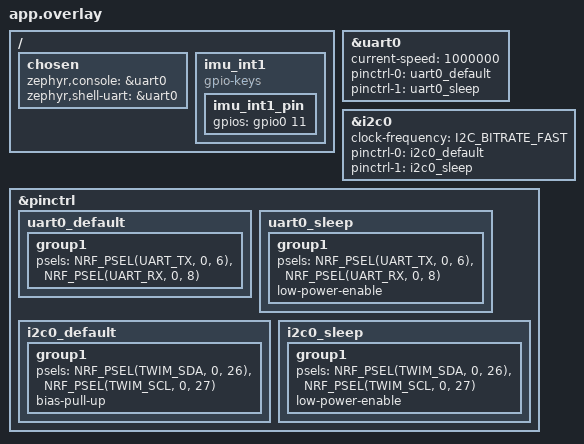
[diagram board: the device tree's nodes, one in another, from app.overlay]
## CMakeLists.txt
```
cmake_minimum_required(VERSION 3.20.0)

find_package(Zephyr REQUIRED HINTS $ENV{ZEPHYR_BASE})

project(imusensor1)

target_sources(app PRIVATE
    src/main.c
    src/imu.c
)

target_include_directories(app PRIVATE
    include
)
```

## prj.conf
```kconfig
CONFIG_MAIN_STACK_SIZE=4096

CONFIG_I2C=y
CONFIG_GPIO=y

CONFIG_LOG=y
CONFIG_LOG_MODE_DEFERRED=y
CONFIG_LOG_DEFAULT_LEVEL=3

CONFIG_CBPRINTF_FP_SUPPORT=y

CONFIG_SERIAL=y
CONFIG_UART_CONSOLE=y
CONFIG_CONSOLE=y
CONFIG_PRINTK=y

CONFIG_LOG_BUFFER_SIZE=32768
CONFIG_LOG_MODE_OVERFLOW=y
CONFIG_LOG_PROCESS_THREAD_STACK_SIZE=4096

CONFIG_NEWLIB_LIBC=y
```

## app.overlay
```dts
/ {
    chosen {
        zephyr,console = &uart0;
        zephyr,shell-uart = &uart0;
    };
};

&uart0 {
    status = "okay";

    current-speed = <1000000>;

    pinctrl-0 = <&uart0_default>;
    pinctrl-1 = <&uart0_sleep>;
    pinctrl-names = "default", "sleep";
};

&i2c0 {
    status = "okay";

    clock-frequency = <I2C_BITRATE_FAST>;

    pinctrl-0 = <&i2c0_default>;
    pinctrl-1 = <&i2c0_sleep>;
    pinctrl-names = "default", "sleep";
};

&pinctrl {

    uart0_default: uart0_default {
        group1 {
            psels = <NRF_PSEL(UART_TX, 0, 6)>,
                    <NRF_PSEL(UART_RX, 0, 8)>;
        };
    };

    uart0_sleep: uart0_sleep {
        group1 {
            psels = <NRF_PSEL(UART_TX, 0, 6)>,
                    <NRF_PSEL(UART_RX, 0, 8)>;
            low-power-enable;
        };
    };

    i2c0_default: i2c0_default {
        group1 {
            psels = <NRF_PSEL(TWIM_SDA, 0, 26)>,
                    <NRF_PSEL(TWIM_SCL, 0, 27)>;
            bias-pull-up;
        };
    };

    i2c0_sleep: i2c0_sleep {
        group1 {
            psels = <NRF_PSEL(TWIM_SDA, 0, 26)>,
                    <NRF_PSEL(TWIM_SCL, 0, 27)>;
            low-power-enable;
        };
    };
};

/* IMU INT1 pin declaration for Zephyr DT.
 * "gpio-keys" is used here only because it is one of the bindings
 * that correctly declares "gpios" as a phandle-array property so
 * GPIO_DT_SPEC_GET()/DT_NODELABEL() resolve correctly. The
 * gpio-keys DRIVER (zephyr,code, key-press semantics, the
 * INPUT subsystem) is NOT used - this pin is read and configured
 * directly via gpio_pin_*() calls in imu.c. */
/ {
    imu_int1 {
        compatible = "gpio-keys";

        imu_int1_pin: imu_int1_pin {
            gpios = <&gpio0 11 GPIO_ACTIVE_HIGH>;
        };
    };
};
```

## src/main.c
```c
#include <zephyr/kernel.h>
#include <zephyr/logging/log.h>
#include <zephyr/sys/printk.h>
#include <zephyr/drivers/gpio.h>  /* Added for onboard LED interaction */

#include "imu.h"

LOG_MODULE_REGISTER(main, LOG_LEVEL_INF);

static uint8_t i2c_error_count = 0U;

/* Devicetree node fetching for the standard onboard nRF LED */
static const struct gpio_dt_spec onboard_led = 
    GPIO_DT_SPEC_GET(DT_ALIAS(led0), gpios);

/* Non-blocking timestamp trackers for the 5-second LED event */
static int64_t blink_end_timestamp = 0;
static int64_t next_toggle_timestamp = 0;
static bool led_is_active = false;

/* Frames to align asynchronous Accel/Gyro FIFO packets */
static struct imu_data current_frame;
static bool has_accel = false;
static bool has_gyro = false;

/*------------------------------------------------------------------
 * Continuous FIFO Flushing
 * Always active. Empties raw hardware frames as they fill up.
 *-----------------------------------------------------------------*/
static void process_fifo_stream(void)
{
    uint16_t words_in_fifo = 0;

    if (imu_get_fifo_sample_count(&words_in_fifo) != 0 || words_in_fifo == 0)
    {
        return;
    }

    struct imu_data packet;
    bool accel_ready;
    bool gyro_ready;

    for (uint16_t i = 0; i < words_in_fifo; i++)
    {
        if (imu_read_fifo_packet(&packet, &accel_ready, &gyro_ready) == 0)
        {
            if (accel_ready)
            {
                current_frame.ax_g = packet.ax_g;
                current_frame.ay_g = packet.ay_g;
                current_frame.az_g = packet.az_g;
                has_accel = true;
            }
            if (gyro_ready)
            {
                current_frame.gx_dps = packet.gx_dps;
                current_frame.gy_dps = packet.gy_dps;
                current_frame.gz_dps = packet.gz_dps;
                has_gyro = true;
            }

            if (has_accel && has_gyro)
            {
                // printk("DATA,0,%.3f,%.3f,%.3f,%.3f,%.3f,%.3f\n",
                //        (double)current_frame.ax_g,
                //        (double)current_frame.ay_g,
                //        (double)current_frame.az_g,
                //        (double)current_frame.gx_dps,
                //        (double)current_frame.gy_dps,
                //        (double)current_frame.gz_dps);
                
                has_accel = false;
                has_gyro = false;
            }
        }
    }
}

/*------------------------------------------------------------------
 * Flat Event Parsing 
 * Instantly outputs matching register state transitions
 *-----------------------------------------------------------------*/
static void parse_hardware_event(imu_hw_event_t event)
{
    switch (event)
    {
        case IMU_HW_EVENT_FALL:
            printk("EVENT,FALL_DETECTED\n");

            printk("DATA,0,%.3f,%.3f,%.3f,%.3f,%.3f,%.3f\n",

                        (double)current_frame.ax_g,
                       (double)current_frame.ay_g,
                        (double)current_frame.az_g,
                        (double)current_frame.gx_dps,
                        (double)current_frame.gy_dps,
                        (double)current_frame.gz_dps);
            
            /* Arm the non-blocking LED state tracking machine
             * 5000ms total window, toggling every 200ms for a rapid alert look */
            blink_end_timestamp = k_uptime_get() + 5000;
            next_toggle_timestamp = k_uptime_get();
            break;

        case IMU_HW_EVENT_NO_FALL:
            printk("EVENT,NO_FALL_STILLNESS\n");
            break;

        case IMU_HW_EVENT_MOTION:
            printk("EVENT,MOTION_ALERT\n");

            printk("DATA,0,%.3f,%.3f,%.3f,%.3f,%.3f,%.3f\n",
                        (double)current_frame.ax_g,
                       (double)current_frame.ay_g,
                       (double)current_frame.az_g,
                       (double)current_frame.gx_dps,
                       (double)current_frame.gy_dps,
                       (double)current_frame.gz_dps);
            break;

        default:
            break;
    }
}

/*------------------------------------------------------------------
 * Non-Blocking LED Coordinator
 * Evaluates timing milestones continuously without halting execution
 *-----------------------------------------------------------------*/
static void update_led_state(void)
{
    int64_t current_time = k_uptime_get();

    if (current_time < blink_end_timestamp)
    {
        /* If the 5-second window is active, check if it's time to toggle the pin */
        if (current_time >= next_toggle_timestamp)
        {
            led_is_active = !led_is_active;
            gpio_pin_set_dt(&onboard_led, led_is_active ? 1 : 0);
            
            /* Schedule next flash edge in 200 milliseconds */
            next_toggle_timestamp = current_time + 200;
        }
    }
    else
    {
        /* 5-second window has elapsed, guarantee the LED turns off completely */
        if (led_is_active)
        {
            led_is_active = false;
            gpio_pin_set_dt(&onboard_led, 0);
        }
    }
}

int main(void)
{
    int ret;

    LOG_INF("Starting Flat Continuous Streaming & Event Detection Firmware");

    /* Initialize the onboard LED GPIO pin */
    if (!gpio_is_ready_dt(&onboard_led))
    {
        LOG_ERR("Onboard nRF LED hardware node not ready");
        return -1;
    }
    
    ret = gpio_pin_configure_dt(&onboard_led, GPIO_OUTPUT_INACTIVE);
    if (ret)
    {
        LOG_ERR("Failed to configure LED pin directional output (%d)", ret);
        return -1;
    }

    /* Initialize baseline sensor communication configurations */
    ret = imu_init();
    if (ret)
    {
        LOG_ERR("IMU registration failed (%d)", ret);
        return -1;
    }

    /* Inject legacy hardware parameters (Free-fall and Stillness registers) */
    ret = imu_configure_hw_features();
    if (ret)
    {
        LOG_ERR("Register feature configuration failed (%d)", ret);
        return -1;
    }

    /* Setup hardware interrupt channels */
    ret = imu_int_init();
    if (ret)
    {
        LOG_ERR("Interrupt registration failed (%d)", ret);
        return -1;
    }

    /* Initial latch clearance check on startup */
    if (imu_int_level() == 1)
    {
        imu_hw_event_t boot_event;
        imu_process_hw_events(&boot_event);
        parse_hardware_event(boot_event);
    }

    struct k_sem *hw_sem = imu_get_hw_event_sem();

    while (1)
    {
        /* Check for an interrupt event with a non-blocking 5ms window */
        if (k_sem_take(hw_sem, K_MSEC(5)) == 0)
        {
            imu_hw_event_t registered_event = IMU_HW_EVENT_NONE;

            if (imu_process_hw_events(&registered_event) != 0)
            {
                i2c_error_count++;
                if (i2c_error_count >= 3U)
                {
                    uint8_t whoami = 0;
                    if (imu_read_register(ISM_REG_WHO_AM_I, &whoami) == 0 && whoami == 0x6BU)
                    {
                        imu_configure_hw_features(); 
                    }
                    i2c_error_count = 0U;
                }
                continue;
            }

            i2c_error_count = 0U;

            if (registered_event != IMU_HW_EVENT_NONE)
            {
                parse_hardware_event(registered_event);
            }
        }

        /* Continually evaluate the asynchronous LED blink timer */
        update_led_state();

        /* Always run the streaming engine unconditionally every loop pass */
        process_fifo_stream();
    }

    return 0;
}
```

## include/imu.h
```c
#ifndef IMU_H
#define IMU_H

#include <stdint.h>
#include <stdbool.h>
#include <zephyr/kernel.h>

/*------------------------------------------------------------------
 * ISM330DHCX Hardware Register Addresses for Embedded Engines
 *-----------------------------------------------------------------*/
#define ISM_REG_FIFO_CTRL1          0x07U  /* FIFO Watermark threshold low bits  */
#define ISM_REG_FIFO_CTRL2          0x08U  /* FIFO Watermark threshold high bits */
#define ISM_REG_FIFO_CTRL3          0x09U  /* Gyro & Accel FIFO batch data rates */
#define ISM_REG_FIFO_CTRL4          0x0AU  /* FIFO operational mode control      */
#define ISM_REG_WHO_AM_I            0x0FU
#define ISM_REG_STATUS_REG          0x1EU
#define ISM_REG_WAKE_UP_SRC         0x1BU  /* Hardware event status register     */
#define ISM_REG_FIFO_STATUS1        0x3AU  /* Remaining unread FIFO words count  */
#define ISM_REG_FIFO_STATUS2        0x3BU  /* FIFO status flags (watermark, ovf) */
#define ISM_REG_TAP_CFG0            0x56U  /* Interrupt latch configuration      */
#define ISM_REG_TAP_CFG2            0x58U  /* Master interrupt enablement        */
#define ISM_REG_WAKE_UP_THS         0x5BU  /* Wake-up & Inactivity threshold     */
#define ISM_REG_WAKE_UP_DUR         0x5CU  /* Wake-up & Inactivity duration      */
#define ISM_REG_FREE_FALL           0x5DU  /* Free-fall threshold & duration     */
#define ISM_REG_MD1_CFG             0x5EU  /* Route hardware events to INT1       */
#define ISM_REG_FIFO_DATA_OUT_TAG   0x78U  /* Identifies type of data in FIFO     */
#define ISM_REG_FIFO_DATA_OUT_X_L   0x79U  /* FIFO data output start address      */

/*------------------------------------------------------------------
 * Hardware Event Source Status Bitmasks
 *-----------------------------------------------------------------*/
#define ISM_WAKE_UP_SRC_FF_IA       0x20U  /* Bit 5: Free-Fall event active   */
#define ISM_WAKE_UP_SRC_SLEEP_IA    0x10U  /* Bit 4: Inactivity state active  */
#define ISM_WAKE_UP_SRC_WU_IA       0x08U  /* Bit 3: Motion Wake-Up active    */

/*------------------------------------------------------------------
 * Hardware FIFO Constants & Tag Identifiers
 *-----------------------------------------------------------------*/
#define ISM_FIFO_TAG_GYRO           0x01U  /* FIFO data belongs to Gyroscope     */
#define ISM_FIFO_TAG_ACCEL          0x02U  /* FIFO data belongs to Accelerometer */

/* FIFO Operational Modes (FIFO_CTRL4)
 * 0x00 = Bypass mode (FIFO turned off)
 * 0x06 = Continuous mode (New data overwrites old data if full) */
#define ISM_FIFO_MODE_BYPASS        0x00U
#define ISM_FIFO_MODE_CONTINUOUS    0x06U

/*------------------------------------------------------------------
 * Custom Legacy Configuration Mappings (±4g Full Scale @ 416Hz)
 *-----------------------------------------------------------------*/

/* FALL CONFIGURATION (Register 0x5D)
 * Bits [7:3] = FF_DUR[4:0] (1 LSB = 1 / ODR = 2.403 ms)
 * 0x06U = 6 samples * 2.4 ms = ~14.4 ms minimal duration requirement.
 * Bits [2:0] = FF_THS[2:0] (100b sets the threshold to exactly 344 mg / ~0.35g) */
#define ISM_FF_THS_344MG            0x04U  
#define ISM_FF_DUR_VAL              (0x06U << 3) 

/* NO-FALL / INACTIVITY CONFIGURATIONS (Registers 0x5B & 0x5C)
 * WAKE_UP_THS (0x5B):
 * Bit [6]   = SLEEP_ON_INACT (1 = enable power saving/stationary tracking)
 * Bits[5:0] = WK_THS (Inactivity threshold: 1 LSB = FS / 64 = 4g / 64 = 62.5 mg)
 * 0x02U = 2 * 62.5 mg = 125 mg stillness baseline window.
 * WAKE_UP_DUR (0x5C):
 * Bits [3:0] = SLEEP_DUR (Stillness duration: 1 LSB = 512 / ODR = 1.23 seconds)
 * 0x02U = 2 * 1.23s = ~2.46 seconds of verified rest required. */
#define ISM_SLEEP_ON_INACT_ENABLE   0x40U
#define ISM_NO_FALL_THS_VAL         0x02U  
#define ISM_NO_FALL_DUR_VAL         0x02U  

/* MD1_CFG (0x5E) Physical Routing Flags
 * Bit 5 = INT1_WU (Route wake-up / motion transitions to INT1)
 * Bit 4 = INT1_FF (Route free-fall state transitions to INT1)
 * Bit 3 = INT1_FIFO_TH (Route FIFO Watermark Threshold to INT1) */
#define ISM_INT1_WU_ENABLE          0x20U
#define ISM_INT1_FF_ENABLE          0x10U
#define ISM_INT1_FIFO_TH_ENABLE     0x08U

/*------------------------------------------------------------------
 * Unified Data and Event Handling Enums / Structures
 *-----------------------------------------------------------------*/
struct imu_data
{
    float ax_g;
    float ay_g;
    float az_g;

    float gx_dps;
    float gy_dps;
    float gz_dps;
};

typedef enum
{
    IMU_HW_EVENT_NONE        = 0,
    IMU_HW_EVENT_FALL        = 1,  /* Built-in engine matched Free-Fall parameters */
    IMU_HW_EVENT_NO_FALL     = 2,  /* Built-in engine matched Stillness parameters */
    IMU_HW_EVENT_MOTION      = 3   /* Built-in engine matched Wake-Up parameters    */
} imu_hw_event_t;

/*------------------------------------------------------------------
 * Driver API Declarations
 *-----------------------------------------------------------------*/
int imu_init(void);
int imu_read_register(uint8_t reg, uint8_t *value);
int imu_write_register(uint8_t reg, uint8_t value);
int imu_get_status(uint8_t *status);

int imu_read_accel(float *ax, float *ay, float *az);
int imu_read_gyro(float *gx, float *gy, float *gz);
int imu_read_all(struct imu_data *data);

/* Hardware Feature Engine & Hardware FIFO Configurations */
int imu_configure_hw_features(void);
int imu_clear_fifo(void);
int imu_get_fifo_sample_count(uint16_t *count);
int imu_read_fifo_packet(struct imu_data *data, bool *accel_ready, bool *gyro_ready);

/* Event processor evaluating WAKE_UP_SRC flags and unlatching the INT pin */
int imu_process_hw_events(imu_hw_event_t *event);

int imu_int_init(void);
int imu_int_level(void);
struct k_sem *imu_get_hw_event_sem(void);

#endif /* IMU_H */
```

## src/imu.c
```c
#include "imu.h"

#include <zephyr/device.h>
#include <zephyr/drivers/i2c.h>
#include <zephyr/kernel.h>
#include <zephyr/devicetree.h>
#include <zephyr/logging/log.h>
#include <zephyr/sys/byteorder.h>
#include <zephyr/drivers/gpio.h>

LOG_MODULE_REGISTER(imu, LOG_LEVEL_INF);

#define CTRL1_XL           0x10U
#define CTRL2_G            0x11U
#define CTRL3_C            0x12U

#define OUTX_L_G           0x22U
#define OUTX_L_A           0x28U

#define WHO_AM_I_VALUE     0x6BU
#define IMU_ADDR_0         0x6AU
#define IMU_ADDR_1         0x6BU

#define XL_FS_4G           (0x02U << 2)
#define G_FS_500DPS        (0x04U << 2)

#define ACC_SENSITIVITY_G     0.000122f
#define GYRO_SENSITIVITY_DPS  0.01750f

static const struct device *i2c_dev;
static uint8_t imu_addr;

K_SEM_DEFINE(hw_event_sem, 0, 1);
static struct gpio_callback imu_cb;

static const struct gpio_dt_spec imu_int =
    GPIO_DT_SPEC_GET(DT_NODELABEL(imu_int1_pin), gpios);

/*------------------------------------------------------------------
 * Low-Level Communication Blocks
 *-----------------------------------------------------------------*/
static int reg_read(uint8_t reg, uint8_t *value)
{
    return i2c_write_read(i2c_dev, imu_addr, &reg, 1, value, 1);
}

static int reg_write(uint8_t reg, uint8_t value)
{
    uint8_t tx[2] = {reg, value};
    return i2c_write(i2c_dev, tx, sizeof(tx), imu_addr);
}

static int burst_read(uint8_t reg, uint8_t *data, uint8_t len)
{
    return i2c_write_read(i2c_dev, imu_addr, &reg, 1, data, len);
}

int imu_read_register(uint8_t reg, uint8_t *value)
{
    return reg_read(reg, value);
}

int imu_write_register(uint8_t reg, uint8_t value)
{
    return reg_write(reg, value);
}

static int detect_sensor(void)
{
    uint8_t whoami = 0;

    imu_addr = IMU_ADDR_0;
    if ((reg_read(ISM_REG_WHO_AM_I, &whoami) == 0) && (whoami == WHO_AM_I_VALUE))
    {
        LOG_INF("ISM330DHCX recognized at address 0x6A");
        return 0;
    }

    imu_addr = IMU_ADDR_1;
    if ((reg_read(ISM_REG_WHO_AM_I, &whoami) == 0) && (whoami == WHO_AM_I_VALUE))
    {
        LOG_INF("ISM330DHCX recognized at address 0x6B");
        return 0;
    }

    return -ENODEV;
}

/*------------------------------------------------------------------
 * Physical Interrupt Service Routine
 *-----------------------------------------------------------------*/
static void imu_gpio_callback(const struct device *port,
                              struct gpio_callback *cb,
                              uint32_t pins)
{
    ARG_UNUSED(port);
    ARG_UNUSED(cb);
    ARG_UNUSED(pins);

    k_sem_give(&hw_event_sem);
}

/*------------------------------------------------------------------
 * Base Core Initializations
 *-----------------------------------------------------------------*/
int imu_init(void)
{
    int ret;

    i2c_dev = DEVICE_DT_GET(DT_NODELABEL(i2c0));
    if (!device_is_ready(i2c_dev))
    {
        LOG_ERR("Physical I2C Master Line Not Ready");
        return -ENODEV;
    }

    ret = detect_sensor();
    if (ret) return ret;

    /* BDU=1, IF_INC=1 for robust multi-byte reading configurations */
    ret = reg_write(CTRL3_C, 0x44);
    if (ret) return ret;

    /* Base sampling configured at 416Hz to drive internal silicon blocks */
    ret = reg_write(CTRL1_XL, ((0x06 << 4) | XL_FS_4G));
    if (ret) return ret;

    ret = reg_write(CTRL2_G, ((0x06 << 4) | G_FS_500DPS));
    if (ret) return ret;

    k_msleep(20);
    return 0;
}

/*------------------------------------------------------------------
 * Advanced Hardware Feature Engine & FIFO Configurations
 *-----------------------------------------------------------------*/
int imu_configure_hw_features(void)
{
    int ret;

    /* 1. LIR=1: Latch the interrupt line until WAKE_UP_SRC is explicitly read */
    ret = reg_write(ISM_REG_TAP_CFG0, 0x01U);
    if (ret) return ret;

    /* 2. Enable physical interrupts globally */
    ret = reg_write(ISM_REG_TAP_CFG2, 0x80U); 
    if (ret) return ret;

    /* 3. Program Built-In Fall properties (~0.35g threshold limit) */
    ret = reg_write(ISM_REG_FREE_FALL, (ISM_FF_DUR_VAL | ISM_FF_THS_344MG));
    if (ret) return ret;

    /* 4. Program Built-In Stillness Threshold (125mg baseline limit) */
    ret = reg_write(ISM_REG_WAKE_UP_THS, (ISM_SLEEP_ON_INACT_ENABLE | ISM_NO_FALL_THS_VAL));
    if (ret) return ret;

    /* 5. Program Built-In Stillness Verification Duration Requirement (~2.46 seconds) */
    ret = reg_write(ISM_REG_WAKE_UP_DUR, ISM_NO_FALL_DUR_VAL);
    if (ret) return ret;

    /* 6. Configure Hardware FIFO Batching 
     * Batch both Accel and Gyro data at the current ODR rate (416Hz) */
    ret = reg_write(ISM_REG_FIFO_CTRL3, 0x66U);
    if (ret) return ret;

    /* 7. Arm Hardware FIFO into Continuous Mode 
     * Stream continuously loops inside the silicon buffer until emptied */
    ret = reg_write(ISM_REG_FIFO_CTRL4, ISM_FIFO_MODE_CONTINUOUS);
    if (ret) return ret;

    /* 8. Route internal event evaluation engine outputs to hardware pin INT1 */
    ret = reg_write(ISM_REG_MD1_CFG, (ISM_INT1_WU_ENABLE | ISM_INT1_FF_ENABLE));
    if (ret) return ret;

    LOG_INF("Inbuilt Fall, No-Fall, and FIFO Hardware Cores Configured Successfully");
    return 0;
}

/*------------------------------------------------------------------
 * Hardware FIFO Management Helper Utilities
 *-----------------------------------------------------------------*/
int imu_clear_fifo(void)
{
    int ret;
    /* Put FIFO into bypass mode to reset pointers and wipe data */
    ret = reg_write(ISM_REG_FIFO_CTRL4, ISM_FIFO_MODE_BYPASS);
    if (ret) return ret;

    /* Re-arm FIFO into continuous mode */
    return reg_write(ISM_REG_FIFO_CTRL4, ISM_FIFO_MODE_CONTINUOUS);
}

int imu_get_fifo_sample_count(uint16_t *count)
{
    uint8_t status1 = 0;
    uint8_t status2 = 0;
    int ret;

    if (count == NULL) return -EINVAL;

    ret = reg_read(ISM_REG_FIFO_STATUS1, &status1);
    if (ret) return -EIO;

    ret = reg_read(ISM_REG_FIFO_STATUS2, &status2);
    if (ret) return -EIO;

    /* Combine upper and lower bits to parse unread words count */
    *count = (uint16_t)status1 | (((uint16_t)status2 & 0x03U) << 8);
    return 0;
}

int imu_read_fifo_packet(struct imu_data *data, bool *accel_ready, bool *gyro_ready)
{
    uint8_t raw_packet[7]; /* 1 Tag Byte + 6 Data Bytes */
    int16_t raw_x, raw_y, raw_z;
    int ret;

    if ((data == NULL) || (accel_ready == NULL) || (gyro_ready == NULL)) return -EINVAL;

    *accel_ready = false;
    *gyro_ready = false;

    /* Read the data block starting directly from the Tag identifier register */
    ret = burst_read(ISM_REG_FIFO_DATA_OUT_TAG, raw_packet, sizeof(raw_packet));
    if (ret) return -EIO;

    uint8_t tag = (raw_packet[0] >> 3) & 0x1FU; /* Extract bits [7:3] for the data tag */

    raw_x = (int16_t)sys_get_le16(&raw_packet[1]);
    raw_y = (int16_t)sys_get_le16(&raw_packet[3]);
    raw_z = (int16_t)sys_get_le16(&raw_packet[5]);

    if (tag == ISM_FIFO_TAG_ACCEL)
    {
        data->ax_g = (float)raw_x * ACC_SENSITIVITY_G;
        data->ay_g = (float)raw_y * ACC_SENSITIVITY_G;
        data->az_g = (float)raw_z * ACC_SENSITIVITY_G;
        *accel_ready = true;
    }
    else if (tag == ISM_FIFO_TAG_GYRO)
    {
        data->gx_dps = (float)raw_x * GYRO_SENSITIVITY_DPS;
        data->gy_dps = (float)raw_y * GYRO_SENSITIVITY_DPS;
        data->gz_dps = (float)raw_z * GYRO_SENSITIVITY_DPS;
        *gyro_ready = true;
    }

    return 0;
}

/*------------------------------------------------------------------
 * Hardware Interrupt Event Interpreter
 *-----------------------------------------------------------------*/
int imu_process_hw_events(imu_hw_event_t *event)
{
    uint8_t src_reg = 0;
    int ret;

    if (event == NULL) return -EINVAL;
    *event = IMU_HW_EVENT_NONE;

    /* Reading this register automatically drops the physical INT1 line back low */
    ret = reg_read(ISM_REG_WAKE_UP_SRC, &src_reg);
    if (ret) return -EIO;

    if ((src_reg & ISM_WAKE_UP_SRC_FF_IA) != 0U)
    {
        *event = IMU_HW_EVENT_FALL;
    }
    else if ((src_reg & ISM_WAKE_UP_SRC_SLEEP_IA) != 0U)
    {
        *event = IMU_HW_EVENT_NO_FALL;
    }
    else if ((src_reg & ISM_WAKE_UP_SRC_WU_IA) != 0U)
    {
        *event = IMU_HW_EVENT_MOTION;
    }

    return 0;
}

/*------------------------------------------------------------------
 * Polling Standard Fallbacks
 *-----------------------------------------------------------------*/
int imu_read_accel(float *ax, float *ay, float *az)
{
    uint8_t raw[6];
    if ((ax == NULL) || (ay == NULL) || (az == NULL)) return -EINVAL;
    if (burst_read(OUTX_L_A, raw, 6)) return -EIO;

    *ax = (float)((int16_t)sys_get_le16(&raw[0])) * ACC_SENSITIVITY_G;
    *ay = (float)((int16_t)sys_get_le16(&raw[2])) * ACC_SENSITIVITY_G;
    *az = (float)((int16_t)sys_get_le16(&raw[4])) * ACC_SENSITIVITY_G;
    return 0;
}

int imu_read_gyro(float *gx, float *gy, float *gz)
{
    uint8_t raw[6];
    if ((gx == NULL) || (gy == NULL) || (gz == NULL)) return -EINVAL;
    if (burst_read(OUTX_L_G, raw, 6)) return -EIO;

    *gx = (float)((int16_t)sys_get_le16(&raw[0])) * GYRO_SENSITIVITY_DPS;
    *gy = (float)((int16_t)sys_get_le16(&raw[2])) * GYRO_SENSITIVITY_DPS;
    *gz = (float)((int16_t)sys_get_le16(&raw[4])) * GYRO_SENSITIVITY_DPS;
    return 0;
}

int imu_read_all(struct imu_data *data)
{
    uint8_t raw[12];
    if (data == NULL) return -EINVAL;
    if (burst_read(OUTX_L_G, raw, sizeof(raw))) return -EIO;

    data->gx_dps = (float)((int16_t)sys_get_le16(&raw[0])) * GYRO_SENSITIVITY_DPS;
    data->gy_dps = (float)((int16_t)sys_get_le16(&raw[2])) * GYRO_SENSITIVITY_DPS;
    data->gz_dps = (float)((int16_t)sys_get_le16(&raw[4])) * GYRO_SENSITIVITY_DPS;

    data->ax_g = (float)((int16_t)sys_get_le16(&raw[6])) * ACC_SENSITIVITY_G;
    data->ay_g = (float)((int16_t)sys_get_le16(&raw[8])) * ACC_SENSITIVITY_G;
    data->az_g = (float)((int16_t)sys_get_le16(&raw[10])) * ACC_SENSITIVITY_G;
    return 0;
}

int imu_get_status(uint8_t *status)
{
    if (status == NULL) return -EINVAL;
    return reg_read(ISM_REG_STATUS_REG, status);
}

int imu_int_init(void)
{
    int ret;
    if (!gpio_is_ready_dt(&imu_int)) return -ENODEV;

    ret = gpio_pin_configure_dt(&imu_int, GPIO_INPUT | GPIO_PULL_DOWN);
    if (ret) return ret;

    gpio_init_callback(&imu_cb, imu_gpio_callback, BIT(imu_int.pin));
    ret = gpio_add_callback(imu_int.port, &imu_cb);
    if (ret) return ret;

    return gpio_pin_interrupt_configure_dt(&imu_int, GPIO_INT_EDGE_TO_ACTIVE);
}

int imu_int_level(void)
{
    return gpio_pin_get_dt(&imu_int);
}

struct k_sem *imu_get_hw_event_sem(void)
{
    return &hw_event_sem;
}
```
